# STM32H745_CM7 register map
File version: 2.5
CPU: CM7 r0p1, little endian, MPU, FPU, 4 interrupt priority bits
Registers are 32-bit, read-write, reset 0x0 unless marked. A register's access mark holds for its fields unless they carry their own. Offsets are from the block's base; lines under a group give offsets from that group; [hi:lo] are bit positions; {n}, {i} and the like mark numbered series; 'fields as' and 'values as' point back to an identical list; <NAME> marks a mode.

## Memory map
0x40008400 CRS size 0x400
0x58003800 COMP1 size 0x400

## Interrupts
137 COMP (COMP1) — COMP1 and COMP2
144 CRS — Clock Recovery System globa

## COMP1
Base 0x58003800
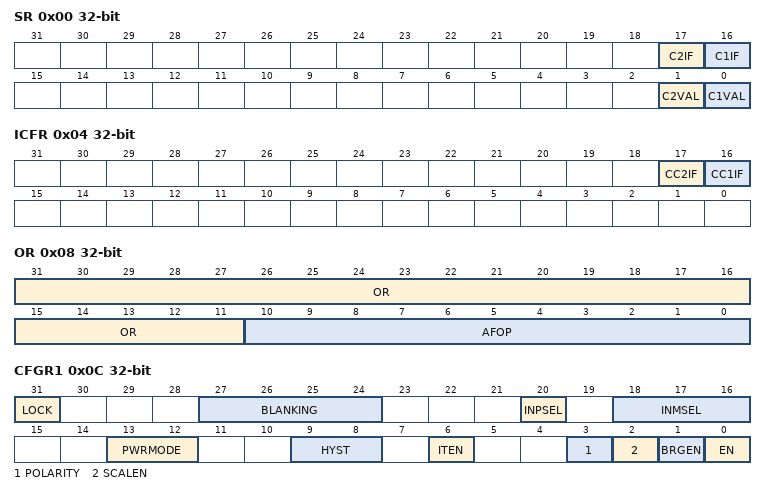
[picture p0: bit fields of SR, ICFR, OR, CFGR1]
0x00 SR ro — Comparator status register
  [17] C2IF — COMP channel 2 Interrupt Flag
  [16] C1IF — COMP channel 1 Interrupt Flag
  [1] C2VAL — COMP channel 2 output status bit
  [0] C1VAL — COMP channel 1 output status bit
0x04 ICFR wo — Comparator interrupt clear flag register
  [17] CC2IF — Clear COMP channel 2 Interrupt Flag
  [16] CC1IF — Clear COMP channel 1 Interrupt Flag
0x08 OR — Comparator option register
  [31:11] OR — Option Register
  [10:0] AFOP — Selection of source for alternate function of output ports
0x0C CFGR1 — Comparator configuration register 1
  [31] LOCK — Lock bit
  [27:24] BLANKING — COMP channel 1 blanking source selection bits
  [20] INPSEL — COMP channel 1 non-inverting input selection bit
  [18:16] INMSEL — COMP channel 1 inverting input selection field
  [13:12] PWRMODE — Power Mode of the COMP channel 1
  [9:8] HYST — COMP channel 1 hysteresis selection bits
  [6] ITEN — COMP channel 1 interrupt enable
  [3] POLARITY — COMP channel 1 polarity selection bit
  [2] SCALEN — Voltage scaler enable bit
  [1] BRGEN — Scaler bridge enable
  [0] EN — COMP channel 1 enable bit
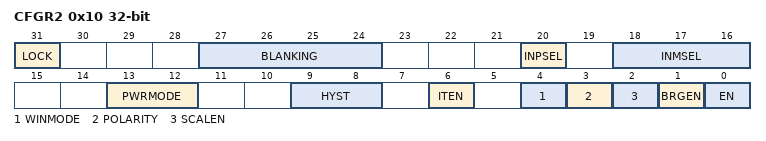
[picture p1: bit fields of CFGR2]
0x10 CFGR2 — Comparator configuration register 2
  [31] LOCK — Lock bit
  [27:24] BLANKING — COMP channel 1 blanking source selection bits
  [20] INPSEL — COMP channel 1 non-inverting input selection bit
  [18:16] INMSEL — COMP channel 1 inverting input selection field
  [13:12] PWRMODE — Power Mode of the COMP channel 1
  [9:8] HYST — COMP channel 1 hysteresis selection bits
  [6] ITEN — COMP channel 1 interrupt enable
  [4] WINMODE — Window comparator mode selection bit
  [3] POLARITY — COMP channel 1 polarity selection bit
  [2] SCALEN — Voltage scaler enable bit
  [1] BRGEN — Scaler bridge enable
  [0] EN — COMP channel 1 enable bit

## Notices in the file
Copyright (c) 2025 STMicroelectronics.
SPDX-License-Identifier: Apache-2.0
Licensed under the Apache License, Version 2.0 (the "License");
you may not use this file except in compliance with the License.
You may obtain a copy of the License at
http://www.apache.org/licenses/LICENSE-2.0
Unless required by applicable law or agreed to in writing, software
distributed under the License is distributed on an "AS IS" BASIS,
WITHOUT WARRANTIES OR CONDITIONS OF ANY KIND, either express or implied.
See the License for the specific language governing permissions and
limitations under the License.
